AUTOSAR XML (schema 00049)
package /UnsetARElements
  executable CM: category=PLATFORM_LEVEL, logging-behavior=USES-LOGGING, reporting-behavior=REPORTS-EXECUTION-STATE, version=1.0.0
    root sw component prototype CmPARA: application-type=CM
  adaptive application sw component type CM
  process CM: executable=CM, state-dependent-startup-config{function-group-state=MachineFG.Startup, resource-group=ResourceGroup0, startup-config=DefaultStartUp}
    process state machine CM: type=ProcessState
  service interface Camera
    namespaces:
      symbol props deepracer
      symbol props cameradata
    events:
      data TimingEvent_100ms: type=uint8_t
  someip service interface deployment Camera: service-interface=Camera, service-interface-id=80, service-interface-version={major-version=1, minor-version=0}
    someip event deployment TimingEvent_100ms: event=Camera/TimingEvent_100ms, event-id=1, serializer=SOMEIP, transport-protocol=UDP
    someip event group Eventgroup_TimingEvent_100ms: event-group-id=1, event=Camera/TimingEvent_100ms
  executable Camera: category=APPLICATION_LEVEL, logging-behavior=USES-LOGGING, reporting-behavior=REPORTS-EXECUTION-STATE, version=0.0.1
    root sw component prototype CameraAA: application-type=Camera
  adaptive application sw component type Camera
    provide port PPortCamera: provided-interface=Camera
  process Camera: executable=Camera, state-dependent-startup-config{function-group-state=DeepRacerFG.Vehicle, resource-group=ResourceGroup0, startup-config=DefaultStartUp}
    process state machine Camera: type=ProcessState
  someip service instance to machine mapping CameraServiceInstanceMapping: communication-connector=eth0, service-instance=Provider_Camera, udp-port=21000
  service instance to port prototype mapping Camera_AA_PPort0: port-prototype=CameraAA.PPortCamera, service-instance=Provider_Camera
  7 x required someip service instance, all with sd-client-config=Consumer_SimulatorSdClientConfig:
    Consumer_Camera: service-interface-deployment=Camera, version-driven-find-behavior=EXACT-OR-ANY-MINOR-VERSION
      someip required event group RequiredEventgroup: event-group=Camera/Eventgroup_TimingEvent_100ms, sd-client-event-group-timing-config=Eventgroup_TimingEvent_100msSdEventgroupConfig
    Consumer_Inferece: service-interface-deployment=Inferece, version-driven-find-behavior=EXACT-OR-ANY-MINOR-VERSION
      someip required event group Eventgroup_TimingEvent_100ms: event-group=Inferece/Eventgroup_TimingEvent_100ms, sd-client-event-group-timing-config=Eventgroup_TimingEvent_100msSdEventgroupConfig
    Consumer_Lidar: service-interface-deployment=Lidar
      someip required event group RequiredEventgroup: event-group=Lidar/Eventgroup_TimingEvent_100ms, sd-client-event-group-timing-config=Eventgroup_TimingEvent_100msSdEventgroupConfig
    Consumer_Navigation: service-interface-deployment=Navigation, version-driven-find-behavior=EXACT-OR-ANY-MINOR-VERSION
      someip required event group Eventgroup_TimingEvent_100ms: event-group=Navigation/Eventgroup_TimingEvent_100ms, sd-client-event-group-timing-config=Eventgroup_TimingEvent_100msSdEventgroupConfig
    Consumer_Navigation_Servo: service-interface-deployment=Servo
      someip required event group RequiredEventgroup: event-group=Servo/Eventgroup_TimingEvent_100ms, sd-client-event-group-timing-config=Eventgroup_TimingEvent_100msSdEventgroupConfig
    Consumer_SensorFusion: service-interface-deployment=SensorFusion, version-driven-find-behavior=EXACT-OR-ANY-MINOR-VERSION
      someip required event group Eventgroup_TimingEvent_100ms: event-group=SensorFusion/Eventgroup_TimingEvent_100ms, sd-client-event-group-timing-config=Eventgroup_TimingEvent_100msSdEventgroupConfig
    Consumer_Simulator: service-interface-deployment=Simulator
      someip required event group RequiredEventgroup: event-group=Simulator/Eventgroup_TimingEvent_100ms, sd-client-event-group-timing-config=Eventgroup_TimingEvent_100msSdEventgroupConfig
  someip sd client service instance config Consumer_SimulatorSdClientConfig: initial-find-behavior={initial-delay-max-value=0.2, initial-delay-min-value=0.1, initial-repetitions-base-delay=0.1, initial-repetitions-max=4}, service-find-time-to-live=16777215
  mode declaration group DeepRacerState: initial-mode=DeepRacerState/Off
    4 x mode:
      Off
      Simulator
      Vehicle
      Verify
  machine DeepracerMachine: machine-design=NetworkDesign_Node_Machine, trusted-platform-executable-launch-behavior=NO-TRUSTED-PLATFORM-SUPPORT
    module-instantiations:
      os module instantiation Linux
        resource group ResourceGroup0
      log and trace instantiation LogAndTraceInstantiation: dlt-ecu-id=Ecu
    processor Processor0  # Intel Atom
      processor core Core: core-id=0
  process to machine mapping set DeepracerProcessToMachineMappingSet
    10 x process to machine mapping, all with machine=DeepracerMachine:
      ProcessToMachineMapping_CM_TO_DeepracerMachine_TO_UnknownModule: process=CM
      ProcessToMachineMapping_Camera_TO_DeepracerMachine_TO_UnknownModule: process=Camera
      ProcessToMachineMapping_EM_TO_DeepracerMachine_TO_UnknownModule: process=EM
      ProcessToMachineMapping_ProcessInference_TO_MachineManifest_Machine_TO_UnknownModule: process=Inference
      ProcessToMachineMapping_ProcessLidar_TO_MachineManifest_Machine_TO_UnknownModule: process=Lidar
      ProcessToMachineMapping_ProcessNavigation_TO_MachineManifest_Machine_TO_UnknownModule: process=Navigation
      ProcessToMachineMapping_ProcessSensorFusion_TO_MachineManifest_Machine_TO_UnknownModule: process=SensorFusion
      ProcessToMachineMapping_ProcessServo_TO_MachineManifest_Machine_TO_UnknownModule: process=Servo
      ProcessToMachineMapping_ProcessSimulator_TO_DeepracerMachine_TO_UnknownModule: process=Simulator
      ProcessToMachineMapping_SM_TO_DeepracerMachine_TO_UnknownModule: process=SM
  composition sw component type ECU
    10 x component:
      CM: type=CM
      Camera: type=Camera
      EM: type=EM
      Inference: type=Inference
      Lidar: type=Lidar
      Navigation: type=Navigation
      SM: type=SM
      SensorFusion: type=SensorFusion
      Servo: type=Servo
      Simulator: type=Simulator
  executable EM: category=PLATFORM_LEVEL, logging-behavior=USES-LOGGING, reporting-behavior=REPORTS-EXECUTION-STATE, version=1.0.0
    root sw component prototype EmPARA: application-type=EM
  adaptive application sw component type EM
  process EM: executable=EM, state-dependent-startup-config{function-group-state=MachineFG.Startup, resource-group=ResourceGroup0, startup-config=DefaultStartUp}
  ethernet cluster Ethernet_Cluster  # DeepRacer IP address: 192.168.1.130
    ethernet physical channel PhysicalChannel0: category=WIRELESS
      network endpoint Loopback: network-endpoint-addresses=ipv-4-configuration={ipv-4-address=127.0.0.1, ipv-4-address-source=FIXED}
      network endpoint NetworkEndpoint: network-endpoint-addresses=ipv-4-configuration={ipv-4-address=172.31.13.179, ipv-4-address-source=FIXED}, priority=1
      network endpoint SdEndpoint: network-endpoint-addresses=ipv-4-configuration={ipv-4-address=224.0.0.1, ipv-4-address-source=FIXED}
  someip sd client event group timing config Eventgroup_TimingEvent_100msSdEventgroupConfig: request-response-delay={max-value=0.0, min-value=0.0}, time-to-live=16777215
  service interface Inferece
    namespaces:
      symbol props deepracer
      symbol props inferencedata
    events:
      data TimingEvent_100ms: type=uint8_t
  someip service interface deployment Inferece: service-interface=Inferece, service-interface-id=83, service-interface-version={major-version=1, minor-version=0}
    someip event deployment TimingEvent_100ms: event=Inferece/TimingEvent_100ms, event-id=1, serializer=SOMEIP, transport-protocol=UDP
    someip event group Eventgroup_TimingEvent_100ms: event-group-id=1, event=Inferece/TimingEvent_100ms
  executable Inference: category=APPLICATION_LEVEL, logging-behavior=USES-LOGGING, reporting-behavior=REPORTS-EXECUTION-STATE, version=0.0.1
    root sw component prototype InferenceAA: application-type=Inference
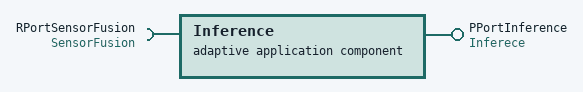
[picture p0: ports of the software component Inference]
  adaptive application sw component type Inference
    provide port PPortInference: provided-interface=Inferece
    require port RPortSensorFusion: required-interface=SensorFusion
  process Inference: executable=Inference, state-dependent-startup-config{execution-dependency=CM.Running, function-group-state=MachineFG.Startup, resource-group=ResourceGroup0, startup-config=DefaultStartUp}
    process state machine Inference: type=ProcessState
  someip service instance to machine mapping InferenceServiceInstanceMapping: communication-connector=eth0, service-instance=[Consumer_SensorFusion, Provider_Inferece], udp-port=21003
  service instance to port prototype mapping Inference_InferenceAA_PPortInference: port-prototype=InferenceAA.PPortInference, service-instance=Provider_Inferece
  service instance to port prototype mapping Inference_InferenceAA_RPortSensorFusion: port-prototype=InferenceAA.RPortSensorFusion, service-instance=Consumer_SensorFusion
  service interface Lidar
    namespaces:
      symbol props deepracer
      symbol props lidardata
    events:
      data TimingEvent_100ms: type=uint8_t
  someip service interface deployment Lidar: service-interface=Lidar, service-interface-id=81, service-interface-version={major-version=1, minor-version=0}
    someip event deployment TimingEvent_100ms: event=Lidar/TimingEvent_100ms, event-id=1, serializer=SOMEIP, transport-protocol=UDP
    someip event group Eventgroup_TimingEvent_100ms: event-group-id=1, event=Lidar/TimingEvent_100ms
  executable Lidar: category=APPLICATION_LEVEL, logging-behavior=USES-LOGGING, reporting-behavior=REPORTS-EXECUTION-STATE, version=0.0.1
    root sw component prototype LidarAA: application-type=Lidar
  adaptive application sw component type Lidar
    provide port PPortLidar: provided-interface=Lidar
  process Lidar: executable=Lidar, state-dependent-startup-config{function-group-state=DeepRacerFG.Vehicle, resource-group=ResourceGroup0, startup-config=DefaultStartUp}
    process state machine Lidar: type=ProcessState
  someip service instance to machine mapping LidarServiceInstanceMapping: communication-connector=eth0, service-instance=Provider_Lidar, udp-port=21001
  service instance to port prototype mapping Lidar_AA_PPort0: port-prototype=LidarAA.PPortLidar, service-instance=Provider_Lidar
  function group set MachineFG
    function-groups:
      mode declaration group prototype DeepRacerFG: type=DeepRacerState
      mode declaration group prototype MachineFG: type=MachineState
  mode declaration group MachineState: initial-mode=MachineState/Off
    5 x mode:
      Off
      Restart
      Shutdown
      Startup
      Verify
  service interface Navigation
    namespaces:
      symbol props deepracer
      symbol props navigationdata
    events:
      data TimingEvent_100ms: type=uint8_t
  someip service interface deployment Navigation: service-interface=Navigation, service-interface-id=84, service-interface-version={major-version=1, minor-version=0}
    someip event deployment TimingEvent_100ms: event=Navigation/TimingEvent_100ms, event-id=1, serializer=SOMEIP, transport-protocol=UDP
    someip event group Eventgroup_TimingEvent_100ms: event-group-id=1, event=Navigation/TimingEvent_100ms
  executable Navigation: category=APPLICATION_LEVEL, logging-behavior=USES-LOGGING, reporting-behavior=REPORTS-EXECUTION-STATE, version=0.0.1
    root sw component prototype NavigationAA: application-type=Navigation
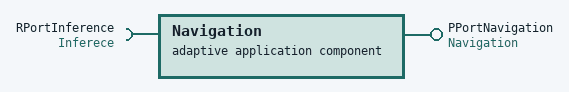
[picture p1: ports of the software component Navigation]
  adaptive application sw component type Navigation
    provide port PPortNavigation: provided-interface=Navigation
    require port RPortInference: required-interface=Inferece
  process Navigation: executable=Navigation, state-dependent-startup-config{execution-dependency=CM.Running, function-group-state=MachineFG.Startup, resource-group=ResourceGroup0, startup-config=DefaultStartUp}
    process state machine Navigation: type=ProcessState
  someip service instance to machine mapping NavigationServiceInstanceMapping: communication-connector=eth0, service-instance=[Consumer_Inferece, Provider_Navigation], udp-port=21004
  service instance to port prototype mapping Navigation_NavigationAA_PPortNavigation: port-prototype=NavigationAA.PPortNavigation, service-instance=Provider_Navigation
  service instance to port prototype mapping Navigation_NavigationAA_RPortInference: port-prototype=NavigationAA.RPortInference, service-instance=Consumer_Inferece
  machine design NetworkDesign_Node_Machine: service-discover-configs=someip-service-discovery={multicast-sd-ip-address=SdEndpoint, someip-service-discovery-port=30490}  # DeepRacer Network Node - Ethernet: To communicate with Simulator - IPC: To communicate between internal AA
    user defined communication connector IPC
    ethernet communication connector eth0: unicast-network-endpoint=NetworkEndpoint
    ethernet communication connector lo: unicast-network-endpoint=Loopback
  mode declaration group ProcessState: initial-mode=Idle
    4 x mode:
      Idle
      Running
      Starting
      Terminated
  6 x provided someip service instance, all with sd-server-config=Provider_SimulatorSdServerConfig:
    Provider_Camera: service-interface-deployment=Camera, someip-event-props=event=Camera/TimingEvent_100ms, service-instance-id=1
      someip provided event group Eventgroup_TimingEvent_100ms: event-group=Camera/Eventgroup_TimingEvent_100ms, multicast-threshold=0
    Provider_Inferece: service-interface-deployment=Inferece, someip-event-props=Inferece/TimingEvent_100ms, service-instance-id=4
      someip provided event group Eventgroup_TimingEvent_100ms: event-group=Inferece/Eventgroup_TimingEvent_100ms, multicast-threshold=0
    Provider_Lidar: service-interface-deployment=Lidar, someip-event-props=Lidar/TimingEvent_100ms, service-instance-id=2
      someip provided event group Eventgroup_TimingEvent_100ms: event-group=Lidar/Eventgroup_TimingEvent_100ms, multicast-threshold=0
    Provider_Navigation: service-interface-deployment=Navigation, someip-event-props=Navigation/TimingEvent_100ms, service-instance-id=5
      someip provided event group Eventgroup_TimingEvent_100ms: event-group=Navigation/Eventgroup_TimingEvent_100ms, multicast-threshold=0
    Provider_SensorFusion: service-interface-deployment=SensorFusion, someip-event-props=event=SensorFusion/TimingEvent_100ms, service-instance-id=3
      someip provided event group Eventgroup_TimingEvent_100ms: event-group=SensorFusion/Eventgroup_TimingEvent_100ms, multicast-threshold=0
    Provider_Simulator: service-interface-deployment=Simulator, someip-event-props=event=Simulator/TimingEvent_100ms, service-instance-id=6
      someip provided event group Eventgroup_TimingEvent_100ms: event-group=Simulator/Eventgroup_TimingEvent_100ms, multicast-threshold=0
  someip sd server service instance config Provider_SimulatorSdServerConfig: initial-offer-behavior={initial-delay-max-value=0.2, initial-delay-min-value=0.1, initial-repetitions-base-delay=0.1, initial-repetitions-max=3}, offer-cyclic-delay=0.5, request-response-delay={max-value=0.0, min-value=0.0}, service-offer-time-to-live=16777215
  executable SM: category=PLATFORM_LEVEL, logging-behavior=USES-LOGGING, reporting-behavior=REPORTS-EXECUTION-STATE, version=1.0.0
    root sw component prototype SmPARA: application-type=SM
  adaptive application sw component type SM
  process SM: executable=SM, state-dependent-startup-config{function-group-state=MachineFG.Startup, resource-group=ResourceGroup0, startup-config=DefaultStartUp}
    process state machine SM: type=ProcessState
  process SensorFusion: executable=SensorFusion, state-dependent-startup-config{execution-dependency=CM.Running, function-group-state=MachineFG.Startup, resource-group=ResourceGroup0, startup-config=DefaultStartUp}
    process state machine SensorFusion: type=ProcessState
  service interface SensorFusion
    namespaces:
      symbol props deepracer
      symbol props sensorfusiondata
    events:
      data TimingEvent_100ms: type=uint8_t
  someip service interface deployment SensorFusion: service-interface=SensorFusion, service-interface-id=82, service-interface-version={major-version=1, minor-version=0}
    someip event deployment TimingEvent_100ms: event=SensorFusion/TimingEvent_100ms, event-id=1, serializer=SOMEIP, transport-protocol=UDP
    someip event group Eventgroup_TimingEvent_100ms: event-group-id=1, event=SensorFusion/TimingEvent_100ms
  executable SensorFusion: category=APPLICATION_LEVEL, logging-behavior=USES-LOGGING, reporting-behavior=REPORTS-EXECUTION-STATE, version=0.0.1
    root sw component prototype SensorFusionAA: application-type=SensorFusion
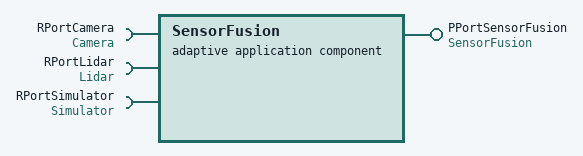
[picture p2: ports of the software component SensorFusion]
  adaptive application sw component type SensorFusion
    provide port PPortSensorFusion: provided-interface=SensorFusion
    require port RPortCamera: required-interface=Camera
    require port RPortLidar: required-interface=Lidar
    require port RPortSimulator: required-interface=Simulator
  4 x service instance to port prototype mapping:
    SensorFusion_AA_PPort0: port-prototype=SensorFusionAA.PPortSensorFusion, service-instance=Provider_SensorFusion
    SensorFusion_SensorFusionAA_RPortCamera: port-prototype=SensorFusionAA.RPortCamera, service-instance=Consumer_Camera
    SensorFusion_SensorFusionAA_RPortLidar: port-prototype=SensorFusionAA.RPortLidar, service-instance=Consumer_Lidar
    SensorFusion_SensorFusionAA_RPortSimulator: port-prototype=SensorFusionAA.RPortSimulator, service-instance=Consumer_Simulator
  someip service instance to machine mapping SensorfusionServiceInstanceMapping: communication-connector=eth0, service-instance=[Consumer_Camera, Consumer_Lidar, Consumer_Simulator, Provider_SensorFusion], udp-port=21002
  process Servo: executable=Servo, state-dependent-startup-config{function-group-state=DeepRacerFG.Vehicle, resource-group=ResourceGroup0, startup-config=DefaultStartUp}
    process state machine Servo: type=ProcessState
  service interface Servo
    namespaces:
      symbol props deepracer
      symbol props servodata
    events:
      data TimingEvent_100ms: type=uint8_t
  someip service interface deployment Servo: service-interface=Servo, service-interface-id=85, service-interface-version={major-version=1, minor-version=0}
    someip event deployment TimingEvent_100ms: event=Servo/TimingEvent_100ms, event-id=1, serializer=SOMEIP, transport-protocol=UDP
    someip event group Eventgroup_TimingEvent_100ms: event-group-id=1, event=Servo/TimingEvent_100ms
  executable Servo: category=APPLICATION_LEVEL, logging-behavior=USES-LOGGING, reporting-behavior=REPORTS-EXECUTION-STATE, version=0.0.1
    root sw component prototype ServoAA: application-type=Servo
  adaptive application sw component type Servo
    require port RPortNavigation: required-interface=Navigation
  someip service instance to machine mapping ServoServiceInstanceMapping: communication-connector=eth0, service-instance=Consumer_Navigation, udp-port=21005
  service instance to port prototype mapping Servo_ServoAA_RPortNavigation: port-prototype=ServoAA.RPortNavigation, service-instance=Consumer_Navigation
  adaptive application sw component type Servo_copy
  process Simulator: executable=Simulator, state-dependent-startup-config{function-group-state=DeepRacerFG.Simulator, resource-group=ResourceGroup0, startup-config=DefaultStartUp}
    process state machine Simulator: type=ProcessState
  service interface Simulator
    namespaces:
      symbol props deepracer
      symbol props simulatordata
    events:
      data TimingEvent_100ms: type=uint8_t
  someip service interface deployment Simulator: service-interface=Simulator, service-interface-id=86, service-interface-version={major-version=1, minor-version=0}
    someip event deployment TimingEvent_100ms: event=Simulator/TimingEvent_100ms, event-id=1, serializer=SOMEIP, transport-protocol=UDP
    someip event group Eventgroup_TimingEvent_100ms: event-group-id=1, event=Simulator/TimingEvent_100ms
  executable Simulator: category=APPLICATION_LEVEL, logging-behavior=USES-LOGGING, reporting-behavior=REPORTS-EXECUTION-STATE, version=0.0.1
    root sw component prototype SimulatorAA: application-type=Simulator
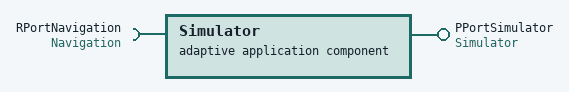
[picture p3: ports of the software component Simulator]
  adaptive application sw component type Simulator
    provide port PPortSimulator: provided-interface=Simulator
    require port RPortNavigation: required-interface=Navigation
  someip service instance to machine mapping SimulatorServiceInstanceMapping: communication-connector=eth0, service-instance=[Consumer_Navigation_Servo, Provider_Simulator], udp-port=21006
  service instance to port prototype mapping Simulator_SimulatorAA_PPort0: port-prototype=SimulatorAA.PPortSimulator, service-instance=Provider_Simulator
  service instance to port prototype mapping Simulator_SimulatorAA_RPortNavigation: port-prototype=SimulatorAA.RPortNavigation, service-instance=Consumer_Navigation
  startup config set StartupConfigSet0
    startup config DefaultStartUp: scheduling-policy=SCHED_OTHER, scheduling-priority=0
  system SystemDesign: category=MACHINE_DESIGN_EXTRACT, system-version=0.0.1  # AWS DeepRacer Evo(Camera: 1, Lidar: 1)
    root-software-compositions:
      root sw composition prototype RootSoftwareComposition: software-composition=ECU
  11 x std cpp implementation data type, all with category=VALUE:
    bool: type-emitter=FundamentalType
    double: type-emitter=FundamentalType
    float: type-emitter=FundamentalType
    int16_t: header-file=cstdint
    int32_t: header-file=cstdint
    int64_t: header-file=cstdint
    int8_t: header-file=cstdint
    uint16_t: header-file=cstdint
    uint32_t: header-file=cstdint
    uint64_t: header-file=cstdint
    uint8_t: header-file=cstdint
